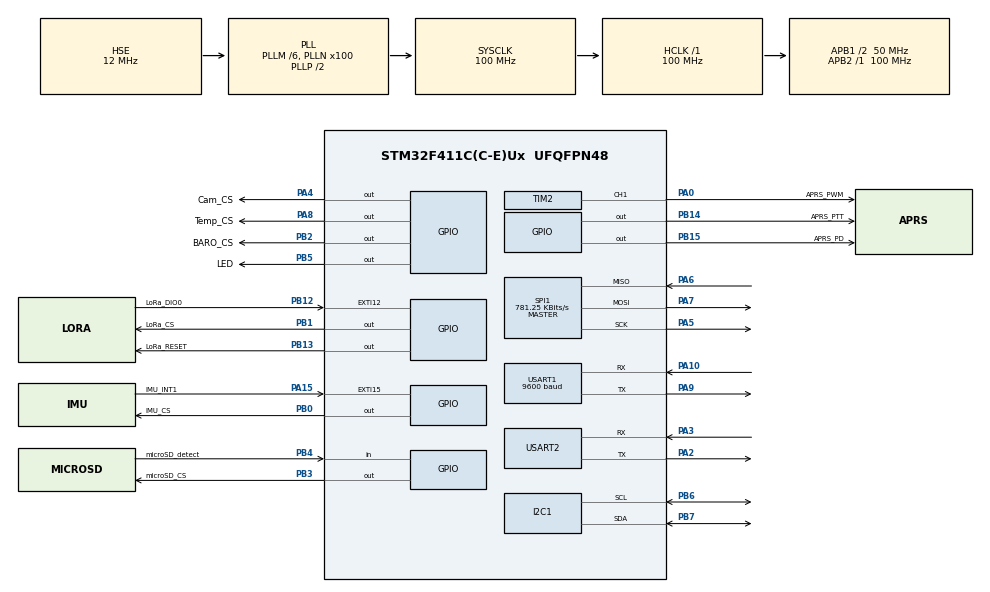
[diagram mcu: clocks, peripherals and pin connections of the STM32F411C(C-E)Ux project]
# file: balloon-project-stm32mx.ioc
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FATFS._MAX_SS=4096
I2C1.I2C_Mode=I2C_Fast
Mcu.Family=STM32F4
Mcu.Name=STM32F411C(C-E)Ux
Mcu.Package=UFQFPN48
NVIC.EXTI15_10_IRQn=true\:0\:0\:false\:false\:true\:true\:true\:true
NVIC.PriorityGroup=NVIC_PRIORITYGROUP_4
NVIC.USART1_IRQn=true\:5\:0\:false\:false\:true\:true\:true\:true
PA0-WKUP.GPIO_Label=APRS_PWM
PA0-WKUP.GPIO_ModeDefaultPP=GPIO_MODE_AF_PP
PA0-WKUP.GPIO_Speed=GPIO_SPEED_FREQ_HIGH
PA0-WKUP.Signal=S_TIM2_CH1_ETR
PA10.GPIO_PuPd=GPIO_PULLUP
PA10.GPIO_Speed=GPIO_SPEED_FREQ_LOW
PA10.Mode=Asynchronous
PA10.Signal=USART1_RX
PA13.Mode=Serial_Wire
PA13.Signal=SYS_JTMS-SWDIO
PA14.Mode=Serial_Wire
PA14.Signal=SYS_JTCK-SWCLK
PA15.GPIO_Label=IMU_INT1
PA15.Signal=GPXTI15
PA2.GPIO_PuPd=GPIO_PULLUP
PA2.GPIO_Speed=GPIO_SPEED_FREQ_LOW
PA2.Mode=Asynchronous
PA2.Signal=USART2_TX
PA3.GPIO_PuPd=GPIO_PULLUP
PA3.GPIO_Speed=GPIO_SPEED_FREQ_LOW
PA3.Mode=Asynchronous
PA3.Signal=USART2_RX
PA4.GPIO_Label=Cam_CS
PA4.GPIO_ModeDefaultOutputPP=GPIO_MODE_OUTPUT_PP
PA4.GPIO_Speed=GPIO_SPEED_FREQ_HIGH
PA4.PinState=GPIO_PIN_SET
PA4.Signal=GPIO_Output
PA5.GPIO_Speed=GPIO_SPEED_FREQ_HIGH
PA5.Mode=Full_Duplex_Master
PA5.Signal=SPI1_SCK
PA6.GPIO_Speed=GPIO_SPEED_FREQ_HIGH
PA6.Mode=Full_Duplex_Master
PA6.Signal=SPI1_MISO
PA7.GPIO_Speed=GPIO_SPEED_FREQ_HIGH
PA7.Mode=Full_Duplex_Master
PA7.Signal=SPI1_MOSI
PA8.GPIO_Label=Temp_CS
PA8.GPIO_Speed=GPIO_SPEED_FREQ_HIGH
PA8.PinState=GPIO_PIN_SET
PA8.Signal=GPIO_Output
PA9.GPIO_PuPd=GPIO_PULLUP
PA9.GPIO_Speed=GPIO_SPEED_FREQ_LOW
PA9.Mode=Asynchronous
PA9.Signal=USART1_TX
PB0.GPIO_Label=IMU_CS
PB0.GPIO_Speed=GPIO_SPEED_FREQ_HIGH
PB0.PinState=GPIO_PIN_SET
PB0.Signal=GPIO_Output
PB1.GPIO_Label=LoRa_CS
PB1.GPIO_Speed=GPIO_SPEED_FREQ_HIGH
PB1.PinState=GPIO_PIN_SET
PB1.Signal=GPIO_Output
PB12.GPIO_Label=LoRa_DIO0
PB12.Signal=GPXTI12
PB13.GPIO_Label=LoRa_RESET
PB13.Signal=GPIO_Output
PB14.GPIO_Label=APRS_PTT
PB14.Signal=GPIO_Output
PB15.GPIO_Label=APRS_PD
PB15.Signal=GPIO_Output
PB2.GPIO_Label=BARO_CS
PB2.GPIO_Speed=GPIO_SPEED_FREQ_HIGH
PB2.PinState=GPIO_PIN_SET
PB2.Signal=GPIO_Output
PB3.GPIO_Label=microSD_CS
PB3.GPIO_Speed=GPIO_SPEED_FREQ_HIGH
PB3.PinState=GPIO_PIN_SET
PB3.Signal=GPIO_Output
PB4.GPIO_Label=microSD_detect
PB4.GPIO_PuPd=GPIO_PULLUP
PB4.Signal=GPIO_Input
PB5.GPIO_Label=LED
PB5.Signal=GPIO_Output
PB6.GPIO_Speed=GPIO_SPEED_FREQ_HIGH
PB6.Mode=I2C
PB6.Signal=I2C1_SCL
PB7.GPIO_Speed=GPIO_SPEED_FREQ_HIGH
PB7.Mode=I2C
PB7.Signal=I2C1_SDA
PH0\ -\ OSC_IN.Mode=HSE-External-Oscillator
PH0\ -\ OSC_IN.Signal=RCC_OSC_IN
PH1\ -\ OSC_OUT.Mode=HSE-External-Oscillator
PH1\ -\ OSC_OUT.Signal=RCC_OSC_OUT
ProjectManager.HeapSize=0x200
ProjectManager.StackSize=0x400
ProjectManager.TargetToolchain=Makefile
RCC.48MHZClocksFreq_Value=50000000
RCC.AHBFreq_Value=100000000
RCC.APB1CLKDivider=RCC_HCLK_DIV2
RCC.APB1Freq_Value=50000000
RCC.APB1TimFreq_Value=100000000
RCC.APB2Freq_Value=100000000
RCC.APB2TimFreq_Value=100000000
RCC.CortexFreq_Value=100000000
RCC.HCLKFreq_Value=100000000
RCC.HSE_VALUE=12000000
RCC.HSI_VALUE=16000000
RCC.LSE_VALUE=32768
RCC.PLLM=6
RCC.PLLN=100
RCC.PLLSourceVirtual=RCC_PLLSOURCE_HSE
RCC.SYSCLKFreq_VALUE=100000000
RCC.SYSCLKSource=RCC_SYSCLKSOURCE_PLLCLK
RCC.VCOOutputFreq_Value=200000000
SH.S_TIM2_CH1_ETR.0=TIM2_CH1,PWM Generation1 CH1
SPI1.BaudRatePrescaler=SPI_BAUDRATEPRESCALER_128
SPI1.CalculateBaudRate=781.25 KBits/s
SPI1.Direction=SPI_DIRECTION_2LINES
SPI1.Mode=SPI_MODE_MASTER
SPI1.VirtualType=VM_MASTER
TIM2.Channel-PWM\ Generation1\ CH1=TIM_CHANNEL_1
USART1.BaudRate=9600
USART1.VirtualMode=VM_ASYNC
USART2.VirtualMode=VM_ASYNC
VP_FATFS_VS_Generic.Mode=User_defined
VP_TIM2_VS_ClockSourceINT.Mode=Internal
board=custom

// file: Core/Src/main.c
/* USER CODE BEGIN Header */
/**
  ******************************************************************************
  * @file           : main.c
  * @brief          : Main program body
  ******************************************************************************
  * @attention
  *
  * Copyright (c) 2026 STMicroelectronics.
  * All rights reserved.
  *
  * This software is licensed under terms that can be found in the LICENSE file
  * in the root directory of this software component.
  * If no LICENSE file comes with this software, it is provided AS-IS.
  *
  ******************************************************************************
  */
/* USER CODE END Header */
#include "main.h"
#include "fatfs.h"

/* USER CODE BEGIN Includes */
#include "app.h"
#include "spi_bus.h"
/* USER CODE END Includes */

I2C_HandleTypeDef hi2c1;

SPI_HandleTypeDef hspi1;

TIM_HandleTypeDef htim2;

UART_HandleTypeDef huart1;
UART_HandleTypeDef huart2;

void SystemClock_Config(void);
static void MX_GPIO_Init(void);
static void MX_I2C1_Init(void);
static void MX_SPI1_Init(void);
static void MX_TIM2_Init(void);
static void MX_USART1_UART_Init(void);
static void MX_USART2_UART_Init(void);

int main(void)
{

  /* MCU Configuration--------------------------------------------------------*/

  /* Reset of all peripherals, Initializes the Flash interface and the Systick. */
  HAL_Init();

  /* Configure the system clock */
  SystemClock_Config();

  /* Initialize all configured peripherals */
  MX_GPIO_Init();
  MX_I2C1_Init();
  MX_SPI1_Init();
  MX_TIM2_Init();
  MX_USART1_UART_Init();
  MX_USART2_UART_Init();
  MX_FATFS_Init();
  /* USER CODE BEGIN 2 */
  (void)spi_bus_init(&hspi1);
  (void)app_init();

  /* Boot indicator: PB5 LED on, and left on for the rest of the run.
     Placed after app_init() so a lit LED means "booted, clocks up, and all
     sensor init completed".

     Standalone-boot diagnostic: powered from battery with no ST-LINK attached,
     this LED should light and stay lit. Lit under the debugger but dark on
     battery means the chip is not executing from flash when it boots on its
     own — check BOOT0 (must be low), the battery rail under load, and NRST.

     PB5 is not in the .ioc, so configure it directly here. */
  for (int i = 0; i<4; i++){
	    HAL_GPIO_TogglePin(LED_GPIO_Port, LED_Pin);
        HAL_Delay(500);
        HAL_GPIO_TogglePin(LED_GPIO_Port, LED_Pin);
        HAL_Delay(500);
  }

  /* Infinite loop */
  while (1)
  {

    /* USER CODE BEGIN 3 */
    app_run();
  }
  /* USER CODE END 3 */
}

void SystemClock_Config(void)
{
  RCC_OscInitTypeDef RCC_OscInitStruct = {0};
  RCC_ClkInitTypeDef RCC_ClkInitStruct = {0};

  /** Configure the main internal regulator output voltage
  */
  __HAL_RCC_PWR_CLK_ENABLE();
  __HAL_PWR_VOLTAGESCALING_CONFIG(PWR_REGULATOR_VOLTAGE_SCALE1);

  /** Initializes the RCC Oscillators according to the specified parameters
  * in the RCC_OscInitTypeDef structure.
  */
  RCC_OscInitStruct.OscillatorType = RCC_OSCILLATORTYPE_HSE;
  RCC_OscInitStruct.HSEState = RCC_HSE_ON;
  RCC_OscInitStruct.PLL.PLLState = RCC_PLL_ON;
  RCC_OscInitStruct.PLL.PLLSource = RCC_PLLSOURCE_HSE;
  RCC_OscInitStruct.PLL.PLLM = 6;
  RCC_OscInitStruct.PLL.PLLN = 100;
  RCC_OscInitStruct.PLL.PLLP = RCC_PLLP_DIV2;
  RCC_OscInitStruct.PLL.PLLQ = 4;
  if (HAL_RCC_OscConfig(&RCC_OscInitStruct) != HAL_OK)
  {
    Error_Handler();
  }

  /** Initializes the CPU, AHB and APB buses clocks
  */
  RCC_ClkInitStruct.ClockType = RCC_CLOCKTYPE_HCLK|RCC_CLOCKTYPE_SYSCLK
                              |RCC_CLOCKTYPE_PCLK1|RCC_CLOCKTYPE_PCLK2;
  RCC_ClkInitStruct.SYSCLKSource = RCC_SYSCLKSOURCE_PLLCLK;
  RCC_ClkInitStruct.AHBCLKDivider = RCC_SYSCLK_DIV1;
  RCC_ClkInitStruct.APB1CLKDivider = RCC_HCLK_DIV2;
  RCC_ClkInitStruct.APB2CLKDivider = RCC_HCLK_DIV1;

  if (HAL_RCC_ClockConfig(&RCC_ClkInitStruct, FLASH_LATENCY_3) != HAL_OK)
  {
    Error_Handler();
  }
}

static void MX_I2C1_Init(void)
{

  hi2c1.Instance = I2C1;
  hi2c1.Init.ClockSpeed = 400000;
  hi2c1.Init.DutyCycle = I2C_DUTYCYCLE_2;
  hi2c1.Init.OwnAddress1 = 0;
  hi2c1.Init.AddressingMode = I2C_ADDRESSINGMODE_7BIT;
  hi2c1.Init.DualAddressMode = I2C_DUALADDRESS_DISABLE;
  hi2c1.Init.OwnAddress2 = 0;
  hi2c1.Init.GeneralCallMode = I2C_GENERALCALL_DISABLE;
  hi2c1.Init.NoStretchMode = I2C_NOSTRETCH_DISABLE;
  if (HAL_I2C_Init(&hi2c1) != HAL_OK)
  {
    Error_Handler();
  }

}

static void MX_SPI1_Init(void)
{

  /* SPI1 parameter configuration*/
  hspi1.Instance = SPI1;
  hspi1.Init.Mode = SPI_MODE_MASTER;
  hspi1.Init.Direction = SPI_DIRECTION_2LINES;
  hspi1.Init.DataSize = SPI_DATASIZE_8BIT;
  hspi1.Init.CLKPolarity = SPI_POLARITY_LOW;
  hspi1.Init.CLKPhase = SPI_PHASE_1EDGE;
  hspi1.Init.NSS = SPI_NSS_SOFT;
  hspi1.Init.BaudRatePrescaler = SPI_BAUDRATEPRESCALER_128;
  hspi1.Init.FirstBit = SPI_FIRSTBIT_MSB;
  hspi1.Init.TIMode = SPI_TIMODE_DISABLE;
  hspi1.Init.CRCCalculation = SPI_CRCCALCULATION_DISABLE;
  hspi1.Init.CRCPolynomial = 10;
  if (HAL_SPI_Init(&hspi1) != HAL_OK)
  {
    Error_Handler();
  }
  /* USER CODE BEGIN SPI1_Init 2 */
  /* Bring-up clock (~0.78 MHz) applied by spi_bus_init() after MX_SPI1_Init — see §2.3. */
  /* USER CODE END SPI1_Init 2 */

}

static void MX_TIM2_Init(void)
{

  TIM_ClockConfigTypeDef sClockSourceConfig = {0};
  TIM_MasterConfigTypeDef sMasterConfig = {0};
  TIM_OC_InitTypeDef sConfigOC = {0};

  htim2.Instance = TIM2;
  htim2.Init.Prescaler = 0;
  htim2.Init.CounterMode = TIM_COUNTERMODE_UP;
  htim2.Init.Period = 4294967295;
  htim2.Init.ClockDivision = TIM_CLOCKDIVISION_DIV1;
  htim2.Init.AutoReloadPreload = TIM_AUTORELOAD_PRELOAD_DISABLE;
  if (HAL_TIM_Base_Init(&htim2) != HAL_OK)
  {
    Error_Handler();
  }
  sClockSourceConfig.ClockSource = TIM_CLOCKSOURCE_INTERNAL;
  if (HAL_TIM_ConfigClockSource(&htim2, &sClockSourceConfig) != HAL_OK)
  {
    Error_Handler();
  }
  if (HAL_TIM_PWM_Init(&htim2) != HAL_OK)
  {
    Error_Handler();
  }
  sMasterConfig.MasterOutputTrigger = TIM_TRGO_RESET;
  sMasterConfig.MasterSlaveMode = TIM_MASTERSLAVEMODE_DISABLE;
  if (HAL_TIMEx_MasterConfigSynchronization(&htim2, &sMasterConfig) != HAL_OK)
  {
    Error_Handler();
  }
  sConfigOC.OCMode = TIM_OCMODE_PWM1;
  sConfigOC.Pulse = 0;
  sConfigOC.OCPolarity = TIM_OCPOLARITY_HIGH;
  sConfigOC.OCFastMode = TIM_OCFAST_DISABLE;
  if (HAL_TIM_PWM_ConfigChannel(&htim2, &sConfigOC, TIM_CHANNEL_1) != HAL_OK)
  {
    Error_Handler();
  }
  HAL_TIM_MspPostInit(&htim2);

}

static void MX_USART1_UART_Init(void)
{

  huart1.Instance = USART1;
  huart1.Init.BaudRate = 9600;
  huart1.Init.WordLength = UART_WORDLENGTH_8B;
  huart1.Init.StopBits = UART_STOPBITS_1;
  huart1.Init.Parity = UART_PARITY_NONE;
  huart1.Init.Mode = UART_MODE_TX_RX;
  huart1.Init.HwFlowCtl = UART_HWCONTROL_NONE;
  huart1.Init.OverSampling = UART_OVERSAMPLING_16;
  if (HAL_UART_Init(&huart1) != HAL_OK)
  {
    Error_Handler();
  }
  /* USER CODE BEGIN USART1_Init 2 */
  /* GPS (MAX-M10S) default NMEA is 9600 8N1 — CubeMX generated 115200. */
  huart1.Init.BaudRate = 9600;
  if (HAL_UART_Init(&huart1) != HAL_OK)
  {
    Error_Handler();
  }
  /* USER CODE END USART1_Init 2 */

}

static void MX_USART2_UART_Init(void)
{

  huart2.Instance = USART2;
  huart2.Init.BaudRate = 115200;
  huart2.Init.WordLength = UART_WORDLENGTH_8B;
  huart2.Init.StopBits = UART_STOPBITS_1;
  huart2.Init.Parity = UART_PARITY_NONE;
  huart2.Init.Mode = UART_MODE_TX_RX;
  huart2.Init.HwFlowCtl = UART_HWCONTROL_NONE;
  huart2.Init.OverSampling = UART_OVERSAMPLING_16;
  if (HAL_UART_Init(&huart2) != HAL_OK)
  {
    Error_Handler();
  }

}

static void MX_GPIO_Init(void)
{
  GPIO_InitTypeDef GPIO_InitStruct = {0};

  /* GPIO Ports Clock Enable */
  __HAL_RCC_GPIOH_CLK_ENABLE();
  __HAL_RCC_GPIOA_CLK_ENABLE();
  __HAL_RCC_GPIOB_CLK_ENABLE();

  /*Configure GPIO pin Output Level */
  HAL_GPIO_WritePin(GPIOA, Cam_CS_Pin|Temp_CS_Pin, GPIO_PIN_SET);

  /*Configure GPIO pin Output Level */
  HAL_GPIO_WritePin(GPIOB, IMU_CS_Pin|LoRa_CS_Pin|BARO_CS_Pin|microSD_CS_Pin, GPIO_PIN_SET);

  /*Configure GPIO pin Output Level */
  HAL_GPIO_WritePin(GPIOB, LoRa_RESET_Pin|APRS_PTT_Pin|APRS_PD_Pin|LED_Pin, GPIO_PIN_RESET);

  /*Configure GPIO pins : Cam_CS_Pin Temp_CS_Pin */
  GPIO_InitStruct.Pin = Cam_CS_Pin|Temp_CS_Pin;
  GPIO_InitStruct.Mode = GPIO_MODE_OUTPUT_PP;
  GPIO_InitStruct.Pull = GPIO_NOPULL;
  GPIO_InitStruct.Speed = GPIO_SPEED_FREQ_HIGH;
  HAL_GPIO_Init(GPIOA, &GPIO_InitStruct);

  /*Configure GPIO pins : IMU_CS_Pin LoRa_CS_Pin BARO_CS_Pin microSD_CS_Pin */
  GPIO_InitStruct.Pin = IMU_CS_Pin|LoRa_CS_Pin|BARO_CS_Pin|microSD_CS_Pin;
  GPIO_InitStruct.Mode = GPIO_MODE_OUTPUT_PP;
  GPIO_InitStruct.Pull = GPIO_NOPULL;
  GPIO_InitStruct.Speed = GPIO_SPEED_FREQ_HIGH;
  HAL_GPIO_Init(GPIOB, &GPIO_InitStruct);

  /*Configure GPIO pin : LoRa_DIO0_Pin */
  GPIO_InitStruct.Pin = LoRa_DIO0_Pin;
  GPIO_InitStruct.Mode = GPIO_MODE_IT_RISING;
  GPIO_InitStruct.Pull = GPIO_NOPULL;
  HAL_GPIO_Init(LoRa_DIO0_GPIO_Port, &GPIO_InitStruct);

  /*Configure GPIO pins : LoRa_RESET_Pin APRS_PTT_Pin APRS_PD_Pin LED_Pin */
  GPIO_InitStruct.Pin = LoRa_RESET_Pin|APRS_PTT_Pin|APRS_PD_Pin|LED_Pin;
  GPIO_InitStruct.Mode = GPIO_MODE_OUTPUT_PP;
  GPIO_InitStruct.Pull = GPIO_NOPULL;
  GPIO_InitStruct.Speed = GPIO_SPEED_FREQ_LOW;
  HAL_GPIO_Init(GPIOB, &GPIO_InitStruct);

  /*Configure GPIO pin : IMU_INT1_Pin */
  GPIO_InitStruct.Pin = IMU_INT1_Pin;
  GPIO_InitStruct.Mode = GPIO_MODE_IT_RISING;
  GPIO_InitStruct.Pull = GPIO_NOPULL;
  HAL_GPIO_Init(IMU_INT1_GPIO_Port, &GPIO_InitStruct);

  /*Configure GPIO pin : microSD_detect_Pin */
  GPIO_InitStruct.Pin = microSD_detect_Pin;
  GPIO_InitStruct.Mode = GPIO_MODE_INPUT;
  GPIO_InitStruct.Pull = GPIO_PULLUP;
  HAL_GPIO_Init(microSD_detect_GPIO_Port, &GPIO_InitStruct);

  /* EXTI interrupt init*/
  HAL_NVIC_SetPriority(EXTI15_10_IRQn, 0, 0);
  HAL_NVIC_EnableIRQ(EXTI15_10_IRQn);

}

void Error_Handler(void)
{
  __disable_irq();
  while (1)
  {
  }
}
